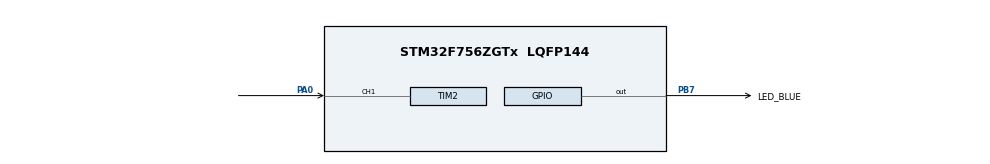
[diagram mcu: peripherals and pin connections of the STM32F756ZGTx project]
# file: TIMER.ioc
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Mcu.Family=STM32F7
TIM2.Channel-Input_Capture1_from_TI1=TIM_CHANNEL_1
PA0/WKUP.Signal=S_TIM2_CH1_ETR
ProjectManager.StackSize=0x400
ProjectManager.TargetToolchain=STM32CubeIDE
RCC.USBFreq_Value=96000000
RCC.LSE_VALUE=32768
RCC.HSE_VALUE=25000000
board=custom
RCC.VCOOutputFreq_Value=192000000
VP_TIM2_VS_ClockSourceINT.Mode=Internal
NVIC.TIM2_IRQn=true\:0\:0\:false\:false\:true\:true\:true
PB7.Signal=GPIO_Output
TIM2.Period=4
Mcu.Name=STM32F756ZGTx
PB7.GPIO_Label=LED_BLUE
Mcu.Package=LQFP144
TIM2.Prescaler=32000-1
SH.S_TIM2_CH1_ETR.0=TIM2_CH1,Input_Capture1_from_TI1
ProjectManager.HeapSize=0x200
RCC.HSI_VALUE=16000000
NVIC.PriorityGroup=NVIC_PRIORITYGROUP_4
RCC.APB1TimFreq_Value=16000000
RCC.APB1Freq_Value=16000000

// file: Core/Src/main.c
/* USER CODE BEGIN Header */
/**
  ******************************************************************************
  * @file           : main.c
  * @brief          : Main program body
  ******************************************************************************
  * @attention
  *
  * <h2><center>&copy; Copyright (c) 2021 STMicroelectronics.
  * All rights reserved.</center></h2>
  *
  * This software component is licensed by ST under BSD 3-Clause license,
  * the "License"; You may not use this file except in compliance with the
  * License. You may obtain a copy of the License at:
  *                        opensource.org/licenses/BSD-3-Clause
  *
  ******************************************************************************
  */
/* USER CODE END Header */
#include "main.h"

TIM_HandleTypeDef htim2;

void SystemClock_Config(void);
static void MX_GPIO_Init(void);
static void MX_TIM2_Init(void);

/* USER CODE BEGIN 0 */
/*void HAL_TIM_PeriodElapsedCallback(TIM_HandleTypeDef *htim)
{
	if(htim -> Instance == TIM2)
	{
		HAL_GPIO_TogglePin(LED_BLUE_GPIO_Port, LED_BLUE_Pin);
	}
}*/
/* USER CODE END 0 */

int main(void)
{

  /* MCU Configuration--------------------------------------------------------*/

  /* Reset of all peripherals, Initializes the Flash interface and the Systick. */
  HAL_Init();

  /* Configure the system clock */
  SystemClock_Config();

  /* Initialize all configured peripherals */
  MX_GPIO_Init();
  MX_TIM2_Init();
  /* USER CODE BEGIN 2 */
  HAL_TIM_Base_Start_IT(&htim2);
  /* USER CODE END 2 */

  /* Infinite loop */
  while (1)
  {

  }
}
void SystemClock_Config(void)
{
  RCC_OscInitTypeDef RCC_OscInitStruct = {0};
  RCC_ClkInitTypeDef RCC_ClkInitStruct = {0};

  /** Configure the main internal regulator output voltage
  */
  __HAL_RCC_PWR_CLK_ENABLE();
  __HAL_PWR_VOLTAGESCALING_CONFIG(PWR_REGULATOR_VOLTAGE_SCALE3);
  /** Initializes the RCC Oscillators according to the specified parameters
  * in the RCC_OscInitTypeDef structure.
  */
  RCC_OscInitStruct.OscillatorType = RCC_OSCILLATORTYPE_HSI;
  RCC_OscInitStruct.HSIState = RCC_HSI_ON;
  RCC_OscInitStruct.HSICalibrationValue = RCC_HSICALIBRATION_DEFAULT;
  RCC_OscInitStruct.PLL.PLLState = RCC_PLL_NONE;
  if (HAL_RCC_OscConfig(&RCC_OscInitStruct) != HAL_OK)
  {
    Error_Handler();
  }
  /** Initializes the CPU, AHB and APB buses clocks
  */
  RCC_ClkInitStruct.ClockType = RCC_CLOCKTYPE_HCLK|RCC_CLOCKTYPE_SYSCLK
                              |RCC_CLOCKTYPE_PCLK1|RCC_CLOCKTYPE_PCLK2;
  RCC_ClkInitStruct.SYSCLKSource = RCC_SYSCLKSOURCE_HSI;
  RCC_ClkInitStruct.AHBCLKDivider = RCC_SYSCLK_DIV1;
  RCC_ClkInitStruct.APB1CLKDivider = RCC_HCLK_DIV1;
  RCC_ClkInitStruct.APB2CLKDivider = RCC_HCLK_DIV1;

  if (HAL_RCC_ClockConfig(&RCC_ClkInitStruct, FLASH_LATENCY_0) != HAL_OK)
  {
    Error_Handler();
  }
}

static void MX_TIM2_Init(void)
{

  TIM_ClockConfigTypeDef sClockSourceConfig = {0};
  TIM_MasterConfigTypeDef sMasterConfig = {0};

  htim2.Instance = TIM2;
  htim2.Init.Prescaler = 32000-1;
  htim2.Init.CounterMode = TIM_COUNTERMODE_UP;
  htim2.Init.Period = 500-1;
  htim2.Init.ClockDivision = TIM_CLOCKDIVISION_DIV1;
  htim2.Init.AutoReloadPreload = TIM_AUTORELOAD_PRELOAD_DISABLE;
  if (HAL_TIM_Base_Init(&htim2) != HAL_OK)
  {
    Error_Handler();
  }
  sClockSourceConfig.ClockSource = TIM_CLOCKSOURCE_INTERNAL;
  if (HAL_TIM_ConfigClockSource(&htim2, &sClockSourceConfig) != HAL_OK)
  {
    Error_Handler();
  }
  sMasterConfig.MasterOutputTrigger = TIM_TRGO_RESET;
  sMasterConfig.MasterSlaveMode = TIM_MASTERSLAVEMODE_DISABLE;
  if (HAL_TIMEx_MasterConfigSynchronization(&htim2, &sMasterConfig) != HAL_OK)
  {
    Error_Handler();
  }

}

static void MX_GPIO_Init(void)
{
  GPIO_InitTypeDef GPIO_InitStruct = {0};

  /* GPIO Ports Clock Enable */
  __HAL_RCC_GPIOB_CLK_ENABLE();

  /*Configure GPIO pin Output Level */
  HAL_GPIO_WritePin(LED_BLUE_GPIO_Port, LED_BLUE_Pin, GPIO_PIN_RESET);

  /*Configure GPIO pin : LED_BLUE_Pin */
  GPIO_InitStruct.Pin = LED_BLUE_Pin;
  GPIO_InitStruct.Mode = GPIO_MODE_OUTPUT_PP;
  GPIO_InitStruct.Pull = GPIO_NOPULL;
  GPIO_InitStruct.Speed = GPIO_SPEED_FREQ_LOW;
  HAL_GPIO_Init(LED_BLUE_GPIO_Port, &GPIO_InitStruct);

}

void Error_Handler(void)
{
  __disable_irq();
  while (1)
  {
  }
}

/************************ (C) COPYRIGHT STMicroelectronics *****END OF FILE****/
